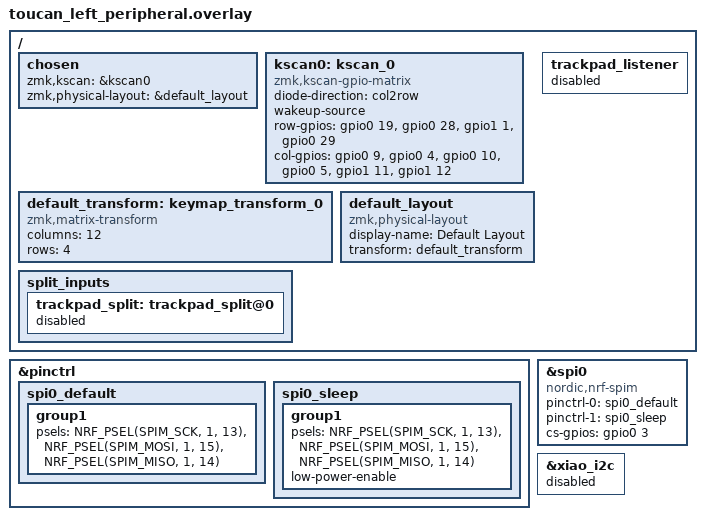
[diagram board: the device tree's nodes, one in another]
// SPDX-License-Identifier: MIT
// Left pin assignments from MuhametSmaili/zmk-keyboard-toucan2 at 6882c95.
// This standalone shield avoids SHIELD_TOUCAN_LEFT, whose fork Kconfig defaults
// force central-only battery services even when ROLE_CENTRAL is disabled.
// keys.h also defines RC() (right Ctrl); load it before the matrix RC(row,col).
#include <dt-bindings/zmk/keys.h>
#include <dt-bindings/zmk/matrix_transform.h>
#include <physical_layouts.dtsi>

/ {
    chosen {
        zmk,kscan = &kscan0;
        zmk,physical-layout = &default_layout;
    };

    kscan0: kscan_0 {
        compatible = "zmk,kscan-gpio-matrix";
        diode-direction = "col2row";
        wakeup-source;
        row-gpios = <&gpio0 19 (GPIO_ACTIVE_HIGH | GPIO_PULL_DOWN)>,
                    <&gpio0 28 (GPIO_ACTIVE_HIGH | GPIO_PULL_DOWN)>,
                    <&gpio1 1 (GPIO_ACTIVE_HIGH | GPIO_PULL_DOWN)>,
                    <&gpio0 29 (GPIO_ACTIVE_HIGH | GPIO_PULL_DOWN)>;
        col-gpios = <&gpio0 9 GPIO_ACTIVE_HIGH>,
                    <&gpio0 4 GPIO_ACTIVE_HIGH>,
                    <&gpio0 10 GPIO_ACTIVE_HIGH>,
                    <&gpio0 5 GPIO_ACTIVE_HIGH>,
                    <&gpio1 11 GPIO_ACTIVE_HIGH>,
                    <&gpio1 12 GPIO_ACTIVE_HIGH>;
    };

    default_transform: keymap_transform_0 {
        compatible = "zmk,matrix-transform";
        columns = <12>;
        rows = <4>;
    };

    default_layout: default_layout {
        compatible = "zmk,physical-layout";
        display-name = "Default Layout";
        transform = <&default_transform>;
    };

    // Only the right half publishes split-input ID 0. These status overrides
    // apply to the shared definitions added by the Toucan keymap.
    split_inputs {
        trackpad_split: trackpad_split@0 {
            status = "disabled";
        };
    };

    trackpad_listener: trackpad_listener {
        status = "disabled";
    };
};

&pinctrl {
    spi0_default: spi0_default {
        group1 {
            psels = <NRF_PSEL(SPIM_SCK, 1, 13)>,
                    <NRF_PSEL(SPIM_MOSI, 1, 15)>,
                    <NRF_PSEL(SPIM_MISO, 1, 14)>;
        };
    };

    spi0_sleep: spi0_sleep {
        group1 {
            psels = <NRF_PSEL(SPIM_SCK, 1, 13)>,
                    <NRF_PSEL(SPIM_MOSI, 1, 15)>,
                    <NRF_PSEL(SPIM_MISO, 1, 14)>;
            low-power-enable;
        };
    };
};

nice_view_spi: &spi0 {
    compatible = "nordic,nrf-spim";
    pinctrl-0 = <&spi0_default>;
    pinctrl-1 = <&spi0_sleep>;
    pinctrl-names = "default", "sleep";
    cs-gpios = <&gpio0 3 GPIO_ACTIVE_HIGH>;
};

&xiao_i2c {
    status = "disabled";
};
